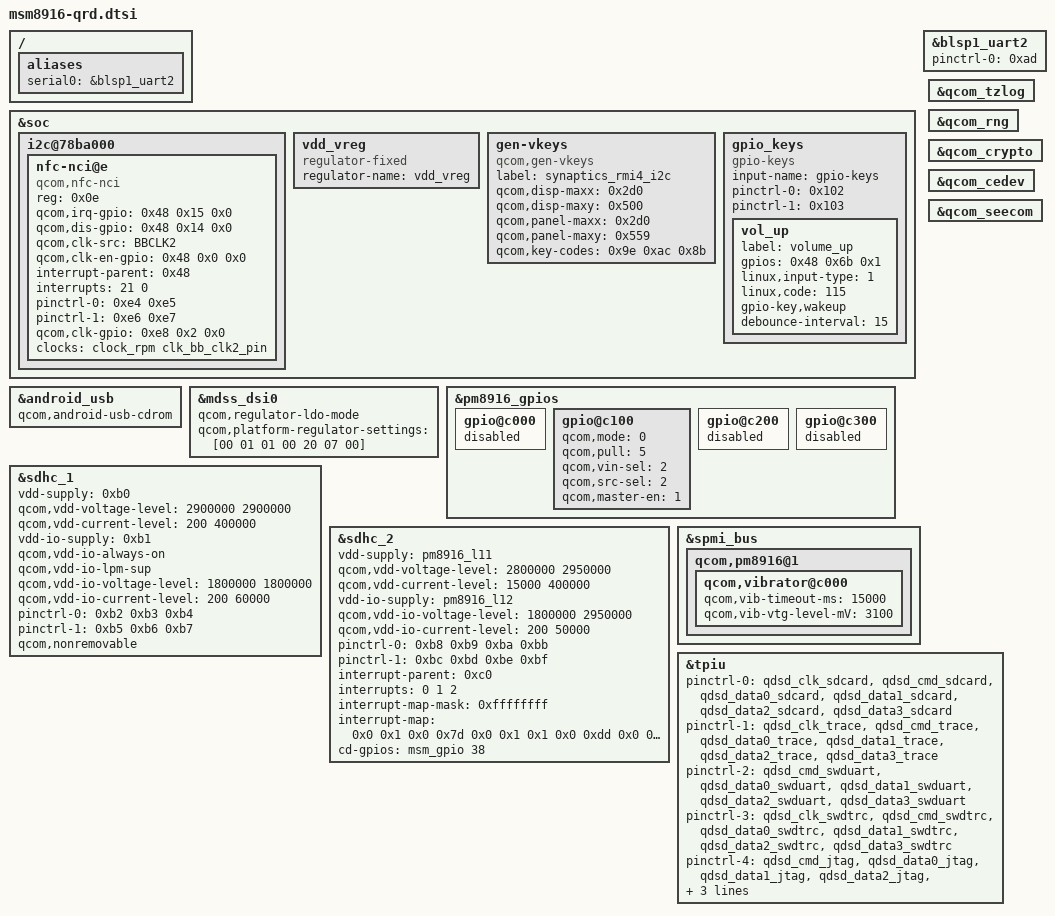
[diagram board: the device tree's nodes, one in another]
/* Copyright (c) 2014, The Linux Foundation. All rights reserved.
 *
 * This program is free software; you can redistribute it and/or modify
 * it under the terms of the GNU General Public License version 2 and
 * only version 2 as published by the Free Software Foundation.
 *
 * This program is distributed in the hope that it will be useful,
 * but WITHOUT ANY WARRANTY; without even the implied warranty of
 * MERCHANTABILITY or FITNESS FOR A PARTICULAR PURPOSE.  See the
 * GNU General Public License for more details.
 */

#include "msm8916.dtsi"
#include "msm8916-pinctrl.dtsi"

/ {
	aliases {
		serial0 = &blsp1_uart2;
	};
};

&soc {
	i2c@78ba000 { /* BLSP1 QUP6 */
		nfc-nci@e {
			compatible = "qcom,nfc-nci";
			reg = <0x0e>;
			qcom,irq-gpio = <0x48 0x15 0x0>;
			qcom,dis-gpio = <0x48 0x14 0x0>;
			qcom,clk-src = "BBCLK2";
			qcom,clk-en-gpio = <0x48 0x0 0x0>;
			interrupt-parent = <0x48>;
			interrupts = <21 0>;
			interrupt-names = "nfc_irq";
			pinctrl-names = "nfc_active","nfc_suspend";
			pinctrl-0 = <0xe4 0xe5>;
			pinctrl-1 = <0xe6 0xe7>;
			qcom,clk-gpio = <0xe8 0x2 0x0>;
			clocks = <&clock_rpm clk_bb_clk2_pin>;
			clock-names = "ref_clk";
		};
	};


};

&android_usb {
	qcom,android-usb-cdrom;
};

&blsp1_uart2 {
	status = "ok";
	pinctrl-names = "default";
	pinctrl-0 = <0xad>;
};

&mdss_dsi0 {
	qcom,regulator-ldo-mode;
	qcom,platform-regulator-settings = [00 01 01 00 20 07 00];
};

&soc {

	vdd_vreg {
		compatible = "regulator-fixed";
		status = "ok";
		regulator-name = "vdd_vreg";
	};

	gen-vkeys {
		compatible = "qcom,gen-vkeys";
		label = "synaptics_rmi4_i2c";
		qcom,disp-maxx = <0x2d0>;
		qcom,disp-maxy = <0x500>;
		qcom,panel-maxx = <0x2d0>;
		qcom,panel-maxy = <0x559>;
		qcom,key-codes = <0x9e 0xac 0x8b>;
	};

	gpio_keys {
		compatible = "gpio-keys";
		input-name = "gpio-keys";
		pinctrl-names = "tlmm_gpio_key_active","tlmm_gpio_key_suspend";
		pinctrl-0 = <0x102>;
		pinctrl-1 = <0x103>;

		vol_up {
			label = "volume_up";
			gpios = <0x48 0x6b 0x1>;
			linux,input-type = <1>;
			linux,code = <115>;
			gpio-key,wakeup;
			debounce-interval = <15>;
		};
	};
};

&pm8916_gpios {
	gpio@c000 { /* GPIO 1 */
		/* Battery UICC Alarm */
		status = "disabled";
	};

	gpio@c100 { /* GPIO 2 */
		/* NFC_CLK_REQ */
		qcom,mode = <0>; /* QPNP_PIN_MODE_DIG_IN */
		qcom,pull = <5>; /* QPNP_PIN_PULL_NO */
		qcom,vin-sel = <2>; /* QPNP_PIN_VIN2 */
		qcom,src-sel = <2>; /* QPNP_PIN_SEL_FUNC_1 */
		qcom,master-en = <1>;
	};

	gpio@c200 { /* GPIO 3 */
		/* External regulator control for WTR */
		status = "disabled";
	};

	gpio@c300 { /* GPIO 4 */
		/* External regulator control for APC */
		status = "disabled";
	};
};

&sdhc_1 {
	vdd-supply = <0xb0>;
	qcom,vdd-voltage-level = <2900000 2900000>;
	qcom,vdd-current-level = <200 400000>;

	vdd-io-supply = <0xb1>;
	qcom,vdd-io-always-on;
	qcom,vdd-io-lpm-sup;
	qcom,vdd-io-voltage-level = <1800000 1800000>;
	qcom,vdd-io-current-level = <200 60000>;

	pinctrl-names = "active", "sleep";
	pinctrl-0 = <0xb2 0xb3 0xb4>;
	pinctrl-1 = <0xb5 0xb6 0xb7>;

	qcom,nonremovable;

	status = "ok";
};

&sdhc_2 {
	vdd-supply = <&pm8916_l11>;
	qcom,vdd-voltage-level = <2800000 2950000>;
	qcom,vdd-current-level = <15000 400000>;

	vdd-io-supply = <&pm8916_l12>;
	qcom,vdd-io-voltage-level = <1800000 2950000>;
	qcom,vdd-io-current-level = <200 50000>;

	pinctrl-names = "active", "sleep";
	pinctrl-0 = <0xb8 0xb9 0xba 0xbb>;
	pinctrl-1 = <0xbc 0xbd 0xbe 0xbf>;

	#address-cells = <0>;
	interrupt-parent = <0xc0>;
	interrupts = <0 1 2>;
	#interrupt-cells = <1>;
	interrupt-map-mask = <0xffffffff>;
	interrupt-map = <0x0 0x1 0x0 0x7d 0x0 0x1 0x1 0x0 0xdd 0x0 0x2 0x48 0x26 0x0>;
	cd-gpios = <0x48 0x26 0x0>;
	cd-gpios = <&msm_gpio 38 0x0>;

	status = "ok";
};

&spmi_bus {
	qcom,pm8916@1 {
		qcom,vibrator@c000 {
			status = "okay";
			qcom,vib-timeout-ms = <15000>;
			qcom,vib-vtg-level-mV = <3100>;
		};
	};
};

&qcom_tzlog {
	status = "okay";
};

&qcom_rng {
	status = "okay";
};

&qcom_crypto {
	status = "okay";
};

&qcom_cedev {
	status = "okay";
};

&qcom_seecom {
	status = "okay";
};

/* CoreSight */
&tpiu {
      pinctrl-names = "sdcard", "trace", "swduart",
		      "swdtrc", "jtag", "spmi";
       /* NIDnT */
      pinctrl-0 = <&qdsd_clk_sdcard &qdsd_cmd_sdcard
                  &qdsd_data0_sdcard &qdsd_data1_sdcard
                  &qdsd_data2_sdcard &qdsd_data3_sdcard>;
      pinctrl-1 = <&qdsd_clk_trace &qdsd_cmd_trace
                  &qdsd_data0_trace &qdsd_data1_trace
                  &qdsd_data2_trace &qdsd_data3_trace>;
      pinctrl-2 = <&qdsd_cmd_swduart &qdsd_data0_swduart
                  &qdsd_data1_swduart &qdsd_data2_swduart
                  &qdsd_data3_swduart>;
      pinctrl-3 = <&qdsd_clk_swdtrc &qdsd_cmd_swdtrc
                  &qdsd_data0_swdtrc &qdsd_data1_swdtrc
                  &qdsd_data2_swdtrc &qdsd_data3_swdtrc>;
      pinctrl-4 = <&qdsd_cmd_jtag &qdsd_data0_jtag
                  &qdsd_data1_jtag &qdsd_data2_jtag
                  &qdsd_data3_jtag>;
      pinctrl-5 = <&qdsd_clk_spmi &qdsd_cmd_spmi
                  &qdsd_data0_spmi &qdsd_data3_spmi>;
};
